AUTOSAR XML (schema 4-0-3)
standard types defined: Boolean, UInt16, UInt8
package /AUTOSAR_Platform/DataConstrs
  range DC_Boolean: raw 0..1
  range DC_UInt16: raw 0..65535
  range DC_UInt8: raw 0..255
package /PATAC/MSM/ComponentTypes
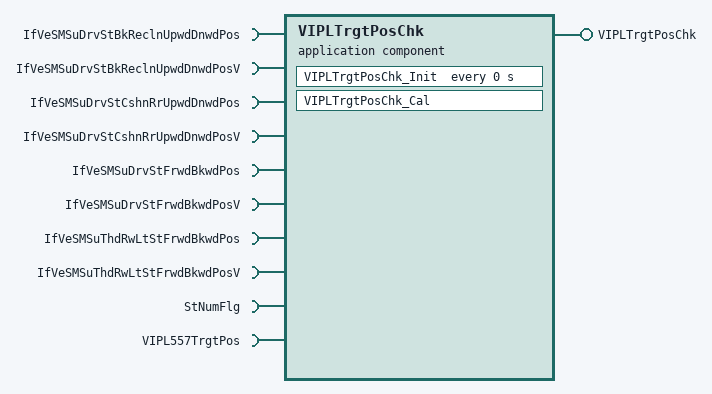
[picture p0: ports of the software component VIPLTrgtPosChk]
  application sw component type VIPLTrgtPosChk
    provide port VIPLTrgtPosChk: server-com-spec{operation=Cal, queue-length=1}, provided-interface=VIPLTrgtPosChk
    10 x require port:
      IfVeSMSuDrvStBkReclnUpwdDnwdPos: nonqueued-receiver-com-spec{data-element=IfVeSMSuDrvStBkReclnUpwdDnwdPos/Val, filter=data-filter-type=ALWAYS, init-value=0}, required-interface=IfVeSMSuDrvStBkReclnUpwdDnwdPos
      IfVeSMSuDrvStBkReclnUpwdDnwdPosV: nonqueued-receiver-com-spec{data-element=IfVeSMSuDrvStBkReclnUpwdDnwdPosV/Val, filter=data-filter-type=ALWAYS, init-value=1}, required-interface=IfVeSMSuDrvStBkReclnUpwdDnwdPosV
      IfVeSMSuDrvStCshnRrUpwdDnwdPos: nonqueued-receiver-com-spec{data-element=IfVeSMSuDrvStCshnRrUpwdDnwdPos/Val, filter=data-filter-type=ALWAYS, init-value=0}, required-interface=IfVeSMSuDrvStCshnRrUpwdDnwdPos
      IfVeSMSuDrvStCshnRrUpwdDnwdPosV: nonqueued-receiver-com-spec{data-element=IfVeSMSuDrvStCshnRrUpwdDnwdPosV/Val, filter=data-filter-type=ALWAYS, init-value=0}, required-interface=IfVeSMSuDrvStCshnRrUpwdDnwdPosV
      IfVeSMSuDrvStFrwdBkwdPos: nonqueued-receiver-com-spec{data-element=IfVeSMSuDrvStFrwdBkwdPos/Val, filter=data-filter-type=ALWAYS, init-value=0}, required-interface=IfVeSMSuDrvStFrwdBkwdPos
      IfVeSMSuDrvStFrwdBkwdPosV: nonqueued-receiver-com-spec{data-element=IfVeSMSuDrvStFrwdBkwdPosV/Val, filter=data-filter-type=ALWAYS, init-value=0}, required-interface=IfVeSMSuDrvStFrwdBkwdPosV
      IfVeSMSuThdRwLtStFrwdBkwdPos: nonqueued-receiver-com-spec{data-element=IfVeSMSuThdRwLtStFrwdBkwdPos/Val, filter=data-filter-type=ALWAYS, init-value=0}, required-interface=IfVeSMSuThdRwLtStFrwdBkwdPos
      IfVeSMSuThdRwLtStFrwdBkwdPosV: nonqueued-receiver-com-spec{data-element=IfVeSMSuThdRwLtStFrwdBkwdPosV/Val, filter=data-filter-type=ALWAYS, init-value=0}, required-interface=IfVeSMSuThdRwLtStFrwdBkwdPosV
      StNumFlg: required-interface=StNumFlg
        required-com-specs:
          data-element=Is4s, filter=data-filter-type=ALWAYS, init-value=0
          data-element=Is6s, filter=data-filter-type=ALWAYS, init-value=0
          data-element=Is6s7s, filter=data-filter-type=ALWAYS, init-value=0
          data-element=Is7s, filter=data-filter-type=ALWAYS, init-value=0
      VIPL557TrgtPos: required-com-specs=[Get, Set], required-interface=VIPL557TrgtPos
    behavior VIPLTrgtPosChk_InternalBehavior
      operation invoked event OIT_VIPLTrgtPosChk_Cal_VIPLTrgtPosChk_Cal: start-on-event=VIPLTrgtPosChk_Cal, operation=VIPLTrgtPosChk.Cal
      timing event VIPLTrgtPosChk_InitEvent: start-on-event=VIPLTrgtPosChk_Init, period=0
      runnable VIPLTrgtPosChk_Cal
        data-receive-point-by-arguments:
          12 x access:
            REC_IfVeSMSuDrvStBkReclnUpwdDnwdPos_Val: accessed-variable=IfVeSMSuDrvStBkReclnUpwdDnwdPos.Val
            REC_IfVeSMSuDrvStBkReclnUpwdDnwdPosV_Val: accessed-variable=IfVeSMSuDrvStBkReclnUpwdDnwdPosV.Val
            REC_IfVeSMSuDrvStCshnRrUpwdDnwdPos_Val: accessed-variable=IfVeSMSuDrvStCshnRrUpwdDnwdPos.Val
            REC_IfVeSMSuDrvStCshnRrUpwdDnwdPosV_Val: accessed-variable=IfVeSMSuDrvStCshnRrUpwdDnwdPosV.Val
            REC_IfVeSMSuDrvStFrwdBkwdPos_Val: accessed-variable=IfVeSMSuDrvStFrwdBkwdPos.Val
            REC_IfVeSMSuDrvStFrwdBkwdPosV_Val: accessed-variable=IfVeSMSuDrvStFrwdBkwdPosV.Val
            REC_IfVeSMSuThdRwLtStFrwdBkwdPos_Val: accessed-variable=IfVeSMSuThdRwLtStFrwdBkwdPos.Val
            REC_IfVeSMSuThdRwLtStFrwdBkwdPosV_Val: accessed-variable=IfVeSMSuThdRwLtStFrwdBkwdPosV.Val
            REC_StNumFlg_Is4s: accessed-variable=StNumFlg.Is4s
            REC_StNumFlg_Is6s: accessed-variable=StNumFlg.Is6s
            REC_StNumFlg_Is6s7s: accessed-variable=StNumFlg.Is6s7s
            REC_StNumFlg_Is7s: accessed-variable=StNumFlg.Is7s
        sync call SC_VIPL557TrgtPos_Set: operation=VIPL557TrgtPos.Set, timeout=0
      runnable VIPLTrgtPosChk_Init
  swc implementation VIPLTrgtPosChk_Implementation: behavior=VIPLTrgtPosChk_InternalBehavior
    code-descriptors:
      code Default: artifact-descriptors=autosar-engineering-object={short-label=Default, category=SWSRC}
package /PATAC/MSM/Intervene/PortInterfaces
  client server interface VIPLTrgtPosChk  # PosAvl：1模式可用 PosAvl：0模式不可用
    operation Cal
      arg PosAvl: type=UInt8, direction=OUT, server-argument-impl-policy=USE-ARGUMENT-TYPE
package /PATAC/MSM/ModeAdjust/Interfaces
  4 x sender receiver interface:
    IfVeSMSuDrvStBkReclnUpwdDnwdPosV: invalidation-policy{data-element=IfVeSMSuDrvStBkReclnUpwdDnwdPosV/Val, handle-invalid=DONT-INVALIDATE}
      data Val: type=Boolean
    IfVeSMSuDrvStCshnRrUpwdDnwdPosV: invalidation-policy{data-element=IfVeSMSuDrvStCshnRrUpwdDnwdPosV/Val, handle-invalid=DONT-INVALIDATE}
      data Val: type=Boolean
    IfVeSMSuDrvStFrwdBkwdPosV: invalidation-policy{data-element=IfVeSMSuDrvStFrwdBkwdPosV/Val, handle-invalid=DONT-INVALIDATE}
      data Val: type=Boolean
    IfVeSMSuThdRwLtStFrwdBkwdPosV: invalidation-policy{data-element=IfVeSMSuThdRwLtStFrwdBkwdPosV/Val, handle-invalid=DONT-INVALIDATE}
      data Val: type=Boolean
package /PATAC/MSM/ModeAdjust/PortInterface
  client server interface VIPL557TrgtPos
    operation Get
      5 x arg, all with type=UInt16, direction=OUT, server-argument-impl-policy=USE-ARGUMENT-TYPE:
        SecRwLtStBkReclnTrgtPos
        SecRwLtStZeroTrgtPos
        SecRwLtStLgrstUpwdDnwdTrgtPos
        SecRwLtStLgrstInwdOtwdTrgtPos
        SecRwLtStFwdBkwdTrgtPos
    operation Set
      5 x arg, all with type=UInt16, direction=IN, server-argument-impl-policy=USE-ARGUMENT-TYPE:
        SecRwLtStBkReclnTrgtPos
        SecRwLtStZeroTrgtPos
        SecRwLtStLgrstUpwdDnwdTrgtPos
        SecRwLtStLgrstInwdOtwdTrgtPos
        SecRwLtStFwdBkwdTrgtPos
  sender receiver interface StNumFlg
    4 x data, all with type=Boolean:
      Is4s
      Is6s
      Is6s7s
      Is7s
    invalidation-policys:
      data-element=Is4s, handle-invalid=DONT-INVALIDATE
      data-element=Is6s, handle-invalid=DONT-INVALIDATE
      data-element=Is6s7s, handle-invalid=DONT-INVALIDATE
      data-element=Is7s, handle-invalid=DONT-INVALIDATE
package /PATAC/MSM/PortInterfaces
  4 x sender receiver interface:
    IfVeSMSuDrvStBkReclnUpwdDnwdPos: invalidation-policy{data-element=IfVeSMSuDrvStBkReclnUpwdDnwdPos/Val, handle-invalid=DONT-INVALIDATE}
      data Val: type=UInt16
    IfVeSMSuDrvStCshnRrUpwdDnwdPos: invalidation-policy{data-element=IfVeSMSuDrvStCshnRrUpwdDnwdPos/Val, handle-invalid=DONT-INVALIDATE}
      data Val: type=UInt16
    IfVeSMSuDrvStFrwdBkwdPos: invalidation-policy{data-element=IfVeSMSuDrvStFrwdBkwdPos/Val, handle-invalid=DONT-INVALIDATE}
      data Val: type=UInt16
    IfVeSMSuThdRwLtStFrwdBkwdPos: invalidation-policy{data-element=IfVeSMSuThdRwLtStFrwdBkwdPos/Val, handle-invalid=DONT-INVALIDATE}
      data Val: type=UInt16
